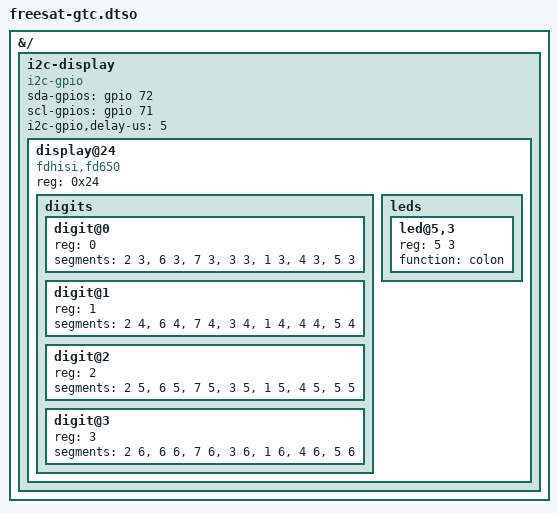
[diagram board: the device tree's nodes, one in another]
/dts-v1/;
/plugin/;

#include <dt-bindings/gpio/gpio.h>
#include <dt-bindings/leds/common.h>

&{/} {

	i2c-display {
		compatible = "i2c-gpio";
		sda-gpios = <&gpio 72 (GPIO_ACTIVE_HIGH | GPIO_OPEN_DRAIN)>;
		scl-gpios = <&gpio 71 (GPIO_ACTIVE_HIGH | GPIO_OPEN_DRAIN)>;
		i2c-gpio,delay-us = <5>;
		#address-cells = <1>;
		#size-cells = <0>;

		display@24 {
			compatible = "fdhisi,fd650", "titanmec,tm1650";
			reg = <0x24>;

			digits {
				#address-cells = <1>;
				#size-cells = <0>;
				digit@0 {
					reg = <0>;
					segments = <2 3>,
						   <6 3>,
						   <7 3>,
						   <3 3>,
						   <1 3>,
						   <4 3>,
						   <5 3>;
				};
				digit@1 {
					reg = <1>;
					segments = <2 4>,
						   <6 4>,
						   <7 4>,
						   <3 4>,
						   <1 4>,
						   <4 4>,
						   <5 4>;
				};
				digit@2 {
					reg = <2>;
					segments = <2 5>,
						   <6 5>,
						   <7 5>,
						   <3 5>,
						   <1 5>,
						   <4 5>,
						   <5 5>;
				};
				digit@3 {
					reg = <3>;
					segments = <2 6>,
						   <6 6>,
						   <7 6>,
						   <3 6>,
						   <1 6>,
						   <4 6>,
						   <5 6>;
				};
			};

			leds {
				#address-cells = <2>;
				#size-cells = <0>;
				led@5,3 {
					reg = <5 3>;
					function = "colon";
				};
			};
		};
	};
};
